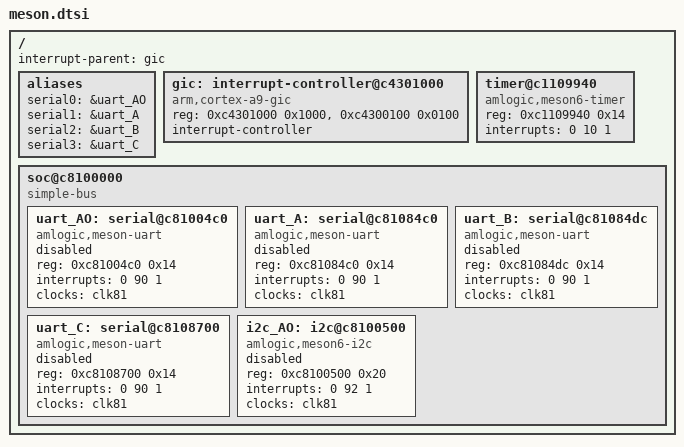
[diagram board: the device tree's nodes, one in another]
/*
 * Copyright 2014 Carlo Caione <carlo@caione.org>
 *
 * This program is free software; you can redistribute it and/or modify it
 * under the terms of the GNU General Public License as published by the
 * Free Software Foundation; either version 2 of the License, or (at your
 * option) any later version.
 */

#include "skeleton.dtsi"

/ {
	interrupt-parent = <&gic>;

	aliases {
		serial0 = &uart_AO;
		serial1 = &uart_A;
		serial2 = &uart_B;
		serial3 = &uart_C;
	};

	gic: interrupt-controller@c4301000 {
		compatible = "arm,cortex-a9-gic";
		reg = <0xc4301000 0x1000>,
		      <0xc4300100 0x0100>;
		interrupt-controller;
		#interrupt-cells = <3>;
	};

	timer@c1109940 {
		compatible = "amlogic,meson6-timer";
		reg = <0xc1109940 0x14>;
		interrupts = <0 10 1>;
	};

	soc@c8100000 {
		compatible = "simple-bus";
		#address-cells = <1>;
		#size-cells = <1>;
		ranges;

		uart_AO: serial@c81004c0 {
			compatible = "amlogic,meson-uart";
			reg = <0xc81004c0 0x14>;
			interrupts = <0 90 1>;
			clocks = <&clk81>;
			status = "disabled";
		};

		uart_A: serial@c81084c0 {
			compatible = "amlogic,meson-uart";
			reg = <0xc81084c0 0x14>;
			interrupts = <0 90 1>;
			clocks = <&clk81>;
			status = "disabled";
		};

		uart_B: serial@c81084dc {
			compatible = "amlogic,meson-uart";
			reg = <0xc81084dc 0x14>;
			interrupts = <0 90 1>;
			clocks = <&clk81>;
			status = "disabled";
		};

		uart_C: serial@c8108700 {
			compatible = "amlogic,meson-uart";
			reg = <0xc8108700 0x14>;
			interrupts = <0 90 1>;
			clocks = <&clk81>;
			status = "disabled";
		};

		i2c_AO: i2c@c8100500 {
			compatible = "amlogic,meson6-i2c";
			reg = <0xc8100500 0x20>;
			interrupts = <0 92 1>;
			clocks = <&clk81>;
			#address-cells = <1>;
			#size-cells = <0>;
			status = "disabled";
		};
	};
}; /* end of / */

